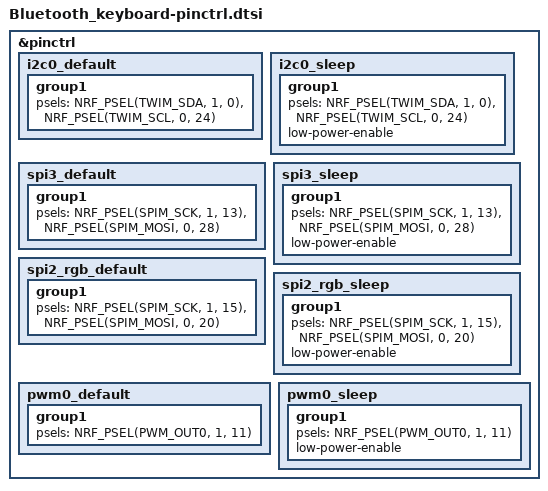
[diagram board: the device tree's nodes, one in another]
&pinctrl {
	i2c0_default: i2c0_default {
		group1 {
			psels = <NRF_PSEL(TWIM_SDA, 1, 0)>,
				<NRF_PSEL(TWIM_SCL, 0, 24)>;
		};
	};

	i2c0_sleep: i2c0_sleep {
		group1 {
			psels = <NRF_PSEL(TWIM_SDA, 1, 0)>,
				<NRF_PSEL(TWIM_SCL, 0, 24)>;
			low-power-enable;
		};
	};

	spi3_default: spi3_default {
		group1 {
			psels = <NRF_PSEL(SPIM_SCK, 1, 13)>,
				<NRF_PSEL(SPIM_MOSI, 0, 28)>;
		};
	};

	spi3_sleep: spi3_sleep {
		group1 {
			psels = <NRF_PSEL(SPIM_SCK, 1, 13)>,
				<NRF_PSEL(SPIM_MOSI, 0, 28)>;
			low-power-enable;
		};
	};

	spi2_rgb_default: spi2_rgb_default {
		group1 {
			psels = <NRF_PSEL(SPIM_SCK, 1, 15)>,
				<NRF_PSEL(SPIM_MOSI, 0, 20)>;
		};
	};

	spi2_rgb_sleep: spi2_rgb_sleep {
		group1 {
			psels = <NRF_PSEL(SPIM_SCK, 1, 15)>,
				<NRF_PSEL(SPIM_MOSI, 0, 20)>;
			low-power-enable;
		};
	};

	pwm0_default: pwm0_default {
		group1 {
			psels = <NRF_PSEL(PWM_OUT0, 1, 11)>;
		};
	};

	pwm0_sleep: pwm0_sleep {
		group1 {
			psels = <NRF_PSEL(PWM_OUT0, 1, 11)>;
			low-power-enable;
		};
	};
};
